VERSION ""

NS_ :

BS_:

BU_: XXX

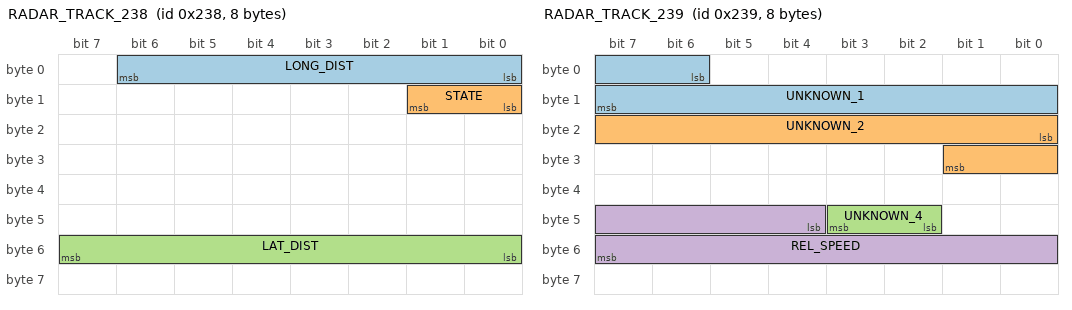
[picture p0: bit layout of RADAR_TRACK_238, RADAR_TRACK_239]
BO_ 568 RADAR_TRACK_238: 8 RADAR
 SG_ LONG_DIST : 6|7@0+ (1,0) [0|127] "m" XXX
 SG_ STATE : 9|2@0+ (1,0) [0|3] "" XXX
 SG_ LAT_DIST : 55|8@0- (0.1,0) [-12.8|12.7] "m" XXX

BO_ 569 RADAR_TRACK_239: 8 RADAR
 SG_ UNKNOWN_1 : 6|10@1+ (1,0) [0|1023] "" XXX
 SG_ UNKNOWN_2 : 16|10@1+ (1,0) [0|1023] "" XXX
 SG_ UNKNOWN_4 : 42|2@1+ (1,0) [0|3] "" XXX
 SG_ REL_SPEED : 44|12@1- (0.016,0) [-32.768|32.752] "m/s" XXX

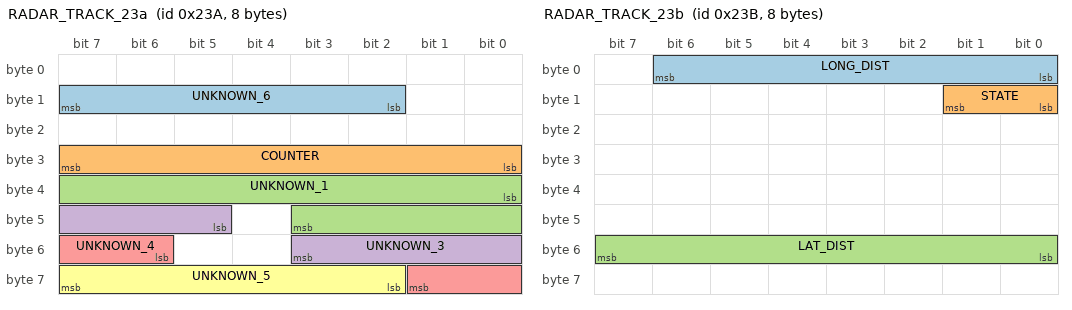
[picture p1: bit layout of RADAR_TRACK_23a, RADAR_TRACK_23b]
BO_ 570 RADAR_TRACK_23a: 8 RADAR
 SG_ UNKNOWN_6 : 10|6@1+ (1,0) [0|63] "" XXX
 SG_ COUNTER : 31|8@0+ (1,0) [0|255] "" XXX
 SG_ UNKNOWN_1 : 32|12@1+ (1,0) [0|4095] "" XXX
 SG_ UNKNOWN_3 : 45|7@1+ (1,0) [0|127] "" XXX
 SG_ UNKNOWN_4 : 54|4@1+ (1,0) [0|15] "" XXX
 SG_ UNKNOWN_5 : 63|6@0+ (1,0) [0|63] "" XXX

BO_ 571 RADAR_TRACK_23b: 8 RADAR
 SG_ LONG_DIST : 6|7@0+ (1,0) [0|127] "m" XXX
 SG_ STATE : 9|2@0+ (1,0) [0|3] "" XXX
 SG_ LAT_DIST : 55|8@0- (0.1,0) [-12.8|12.7] "m" XXX

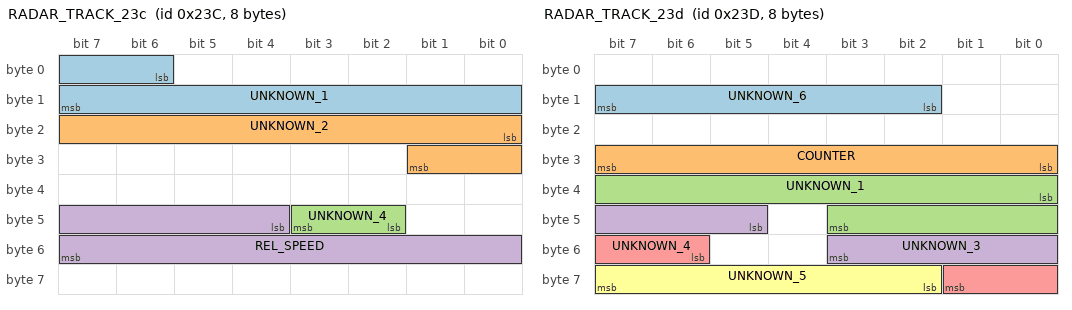
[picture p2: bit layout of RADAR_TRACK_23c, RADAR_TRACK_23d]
BO_ 572 RADAR_TRACK_23c: 8 RADAR
 SG_ UNKNOWN_1 : 6|10@1+ (1,0) [0|1023] "" XXX
 SG_ UNKNOWN_2 : 16|10@1+ (1,0) [0|1023] "" XXX
 SG_ UNKNOWN_4 : 42|2@1+ (1,0) [0|3] "" XXX
 SG_ REL_SPEED : 44|12@1- (0.016,0) [-32.768|32.752] "m/s" XXX

BO_ 573 RADAR_TRACK_23d: 8 RADAR
 SG_ UNKNOWN_6 : 10|6@1+ (1,0) [0|63] "" XXX
 SG_ COUNTER : 31|8@0+ (1,0) [0|255] "" XXX
 SG_ UNKNOWN_1 : 32|12@1+ (1,0) [0|4095] "" XXX
 SG_ UNKNOWN_3 : 45|7@1+ (1,0) [0|127] "" XXX
 SG_ UNKNOWN_4 : 54|4@1+ (1,0) [0|15] "" XXX
 SG_ UNKNOWN_5 : 63|6@0+ (1,0) [0|63] "" XXX

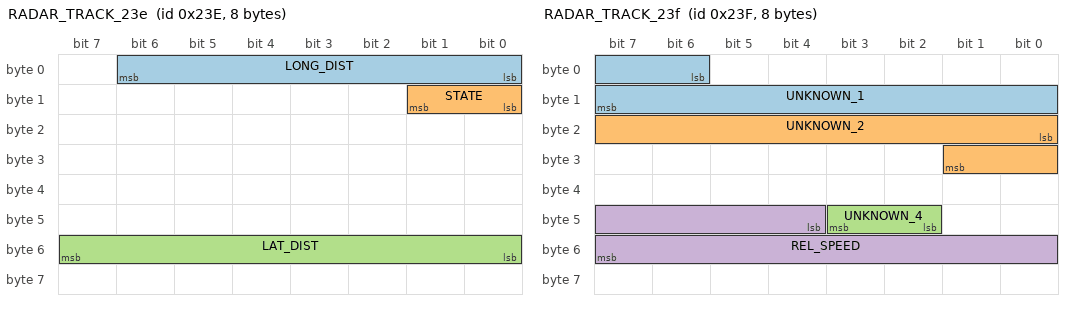
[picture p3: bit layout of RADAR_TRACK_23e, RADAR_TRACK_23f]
BO_ 574 RADAR_TRACK_23e: 8 RADAR
 SG_ LONG_DIST : 6|7@0+ (1,0) [0|127] "m" XXX
 SG_ STATE : 9|2@0+ (1,0) [0|3] "" XXX
 SG_ LAT_DIST : 55|8@0- (0.1,0) [-12.8|12.7] "m" XXX

BO_ 575 RADAR_TRACK_23f: 8 RADAR
 SG_ UNKNOWN_1 : 6|10@1+ (1,0) [0|1023] "" XXX
 SG_ UNKNOWN_2 : 16|10@1+ (1,0) [0|1023] "" XXX
 SG_ UNKNOWN_4 : 42|2@1+ (1,0) [0|3] "" XXX
 SG_ REL_SPEED : 44|12@1- (0.016,0) [-32.768|32.752] "m/s" XXX

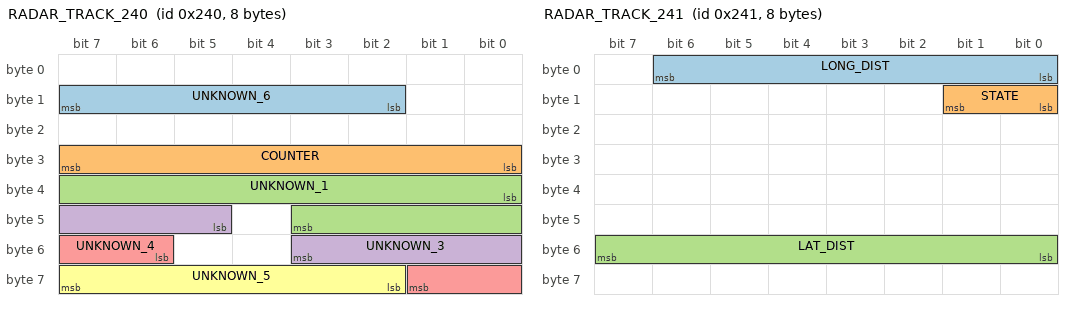
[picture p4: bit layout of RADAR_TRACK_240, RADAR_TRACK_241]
BO_ 576 RADAR_TRACK_240: 8 RADAR
 SG_ UNKNOWN_6 : 10|6@1+ (1,0) [0|63] "" XXX
 SG_ COUNTER : 31|8@0+ (1,0) [0|255] "" XXX
 SG_ UNKNOWN_1 : 32|12@1+ (1,0) [0|4095] "" XXX
 SG_ UNKNOWN_3 : 45|7@1+ (1,0) [0|127] "" XXX
 SG_ UNKNOWN_4 : 54|4@1+ (1,0) [0|15] "" XXX
 SG_ UNKNOWN_5 : 63|6@0+ (1,0) [0|63] "" XXX

BO_ 577 RADAR_TRACK_241: 8 RADAR
 SG_ LONG_DIST : 6|7@0+ (1,0) [0|127] "m" XXX
 SG_ STATE : 9|2@0+ (1,0) [0|3] "" XXX
 SG_ LAT_DIST : 55|8@0- (0.1,0) [-12.8|12.7] "m" XXX

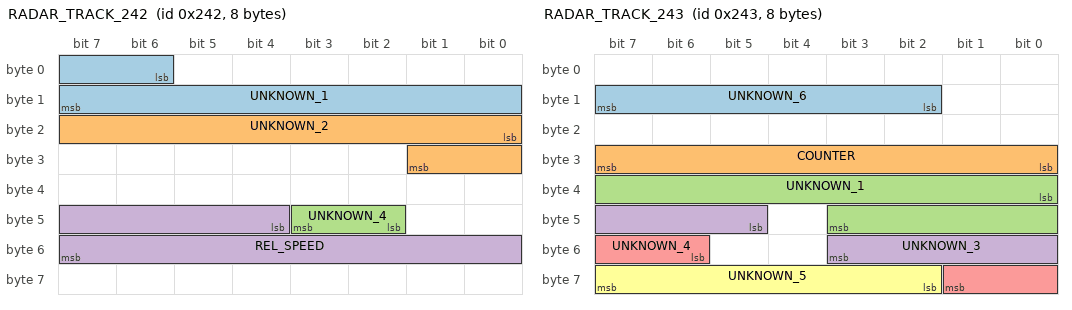
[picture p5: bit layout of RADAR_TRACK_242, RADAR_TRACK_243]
BO_ 578 RADAR_TRACK_242: 8 RADAR
 SG_ UNKNOWN_1 : 6|10@1+ (1,0) [0|1023] "" XXX
 SG_ UNKNOWN_2 : 16|10@1+ (1,0) [0|1023] "" XXX
 SG_ UNKNOWN_4 : 42|2@1+ (1,0) [0|3] "" XXX
 SG_ REL_SPEED : 44|12@1- (0.016,0) [-32.768|32.752] "m/s" XXX

BO_ 579 RADAR_TRACK_243: 8 RADAR
 SG_ UNKNOWN_6 : 10|6@1+ (1,0) [0|63] "" XXX
 SG_ COUNTER : 31|8@0+ (1,0) [0|255] "" XXX
 SG_ UNKNOWN_1 : 32|12@1+ (1,0) [0|4095] "" XXX
 SG_ UNKNOWN_3 : 45|7@1+ (1,0) [0|127] "" XXX
 SG_ UNKNOWN_4 : 54|4@1+ (1,0) [0|15] "" XXX
 SG_ UNKNOWN_5 : 63|6@0+ (1,0) [0|63] "" XXX

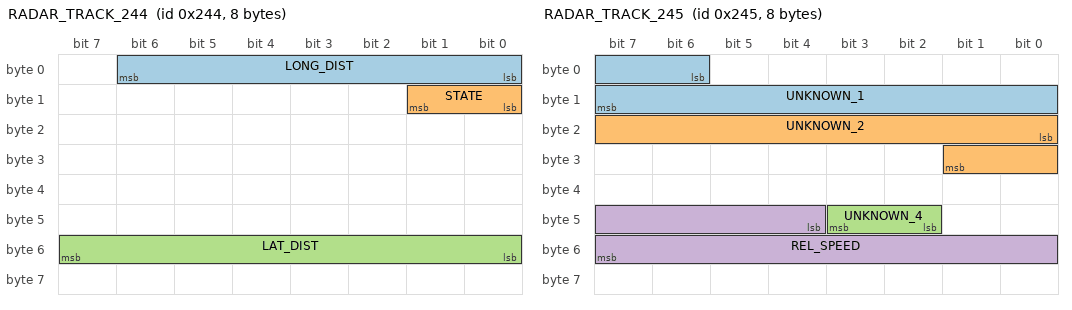
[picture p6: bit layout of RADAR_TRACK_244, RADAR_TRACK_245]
BO_ 580 RADAR_TRACK_244: 8 RADAR
 SG_ LONG_DIST : 6|7@0+ (1,0) [0|127] "m" XXX
 SG_ STATE : 9|2@0+ (1,0) [0|3] "" XXX
 SG_ LAT_DIST : 55|8@0- (0.1,0) [-12.8|12.7] "m" XXX

BO_ 581 RADAR_TRACK_245: 8 RADAR
 SG_ UNKNOWN_1 : 6|10@1+ (1,0) [0|1023] "" XXX
 SG_ UNKNOWN_2 : 16|10@1+ (1,0) [0|1023] "" XXX
 SG_ UNKNOWN_4 : 42|2@1+ (1,0) [0|3] "" XXX
 SG_ REL_SPEED : 44|12@1- (0.016,0) [-32.768|32.752] "m/s" XXX

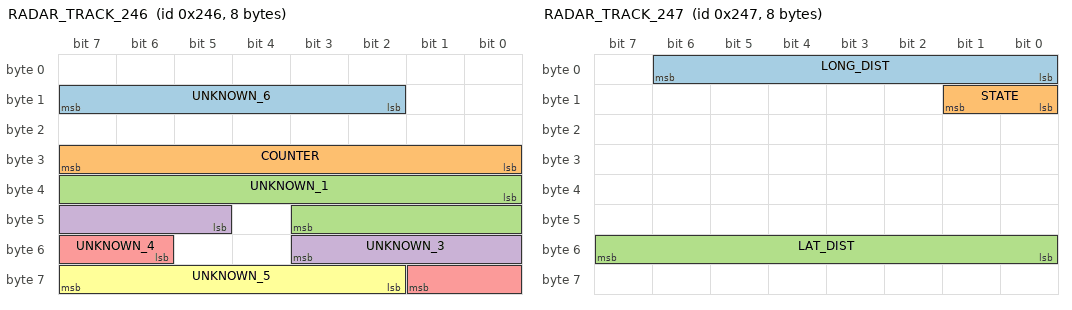
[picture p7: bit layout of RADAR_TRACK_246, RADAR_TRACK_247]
BO_ 582 RADAR_TRACK_246: 8 RADAR
 SG_ UNKNOWN_6 : 10|6@1+ (1,0) [0|63] "" XXX
 SG_ COUNTER : 31|8@0+ (1,0) [0|255] "" XXX
 SG_ UNKNOWN_1 : 32|12@1+ (1,0) [0|4095] "" XXX
 SG_ UNKNOWN_3 : 45|7@1+ (1,0) [0|127] "" XXX
 SG_ UNKNOWN_4 : 54|4@1+ (1,0) [0|15] "" XXX
 SG_ UNKNOWN_5 : 63|6@0+ (1,0) [0|63] "" XXX

BO_ 583 RADAR_TRACK_247: 8 RADAR
 SG_ LONG_DIST : 6|7@0+ (1,0) [0|127] "m" XXX
 SG_ STATE : 9|2@0+ (1,0) [0|3] "" XXX
 SG_ LAT_DIST : 55|8@0- (0.1,0) [-12.8|12.7] "m" XXX

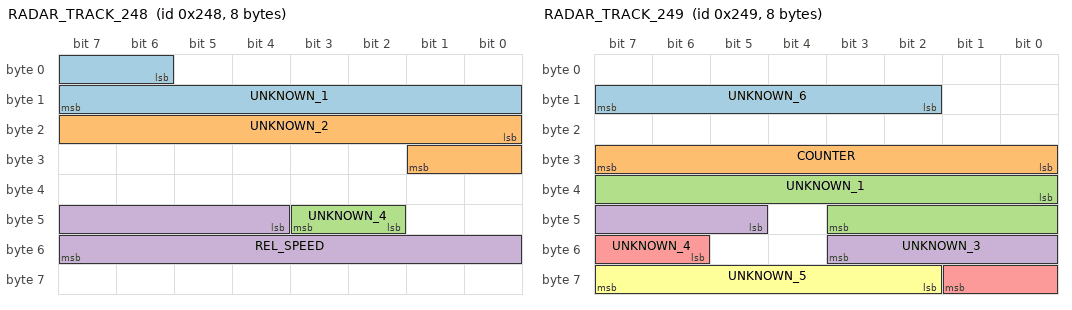
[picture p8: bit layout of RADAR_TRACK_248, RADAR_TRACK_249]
BO_ 584 RADAR_TRACK_248: 8 RADAR
 SG_ UNKNOWN_1 : 6|10@1+ (1,0) [0|1023] "" XXX
 SG_ UNKNOWN_2 : 16|10@1+ (1,0) [0|1023] "" XXX
 SG_ UNKNOWN_4 : 42|2@1+ (1,0) [0|3] "" XXX
 SG_ REL_SPEED : 44|12@1- (0.016,0) [-32.768|32.752] "m/s" XXX

BO_ 585 RADAR_TRACK_249: 8 RADAR
 SG_ UNKNOWN_6 : 10|6@1+ (1,0) [0|63] "" XXX
 SG_ COUNTER : 31|8@0+ (1,0) [0|255] "" XXX
 SG_ UNKNOWN_1 : 32|12@1+ (1,0) [0|4095] "" XXX
 SG_ UNKNOWN_3 : 45|7@1+ (1,0) [0|127] "" XXX
 SG_ UNKNOWN_4 : 54|4@1+ (1,0) [0|15] "" XXX
 SG_ UNKNOWN_5 : 63|6@0+ (1,0) [0|63] "" XXX

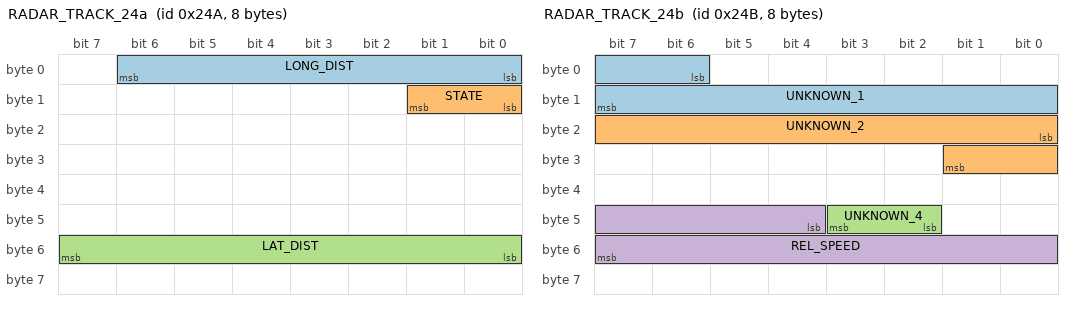
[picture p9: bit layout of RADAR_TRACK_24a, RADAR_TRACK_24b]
BO_ 586 RADAR_TRACK_24a: 8 RADAR
 SG_ LONG_DIST : 6|7@0+ (1,0) [0|127] "m" XXX
 SG_ STATE : 9|2@0+ (1,0) [0|3] "" XXX
 SG_ LAT_DIST : 55|8@0- (0.1,0) [-12.8|12.7] "m" XXX

BO_ 587 RADAR_TRACK_24b: 8 RADAR
 SG_ UNKNOWN_1 : 6|10@1+ (1,0) [0|1023] "" XXX
 SG_ UNKNOWN_2 : 16|10@1+ (1,0) [0|1023] "" XXX
 SG_ UNKNOWN_4 : 42|2@1+ (1,0) [0|3] "" XXX
 SG_ REL_SPEED : 44|12@1- (0.016,0) [-32.768|32.752] "m/s" XXX

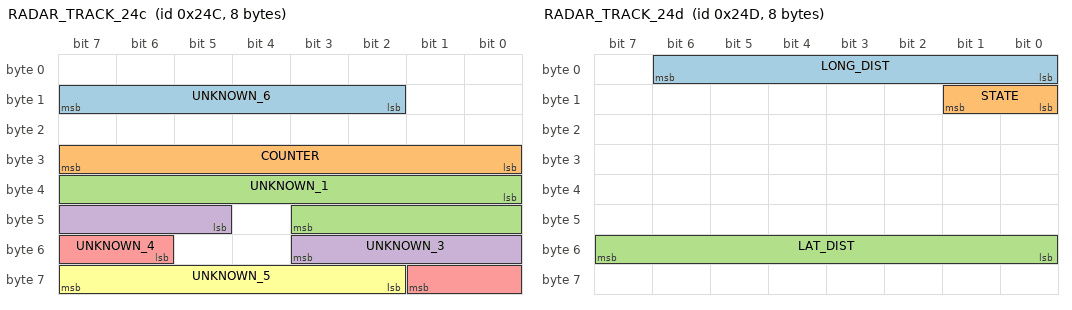
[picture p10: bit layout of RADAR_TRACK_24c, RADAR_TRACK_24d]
BO_ 588 RADAR_TRACK_24c: 8 RADAR
 SG_ UNKNOWN_6 : 10|6@1+ (1,0) [0|63] "" XXX
 SG_ COUNTER : 31|8@0+ (1,0) [0|255] "" XXX
 SG_ UNKNOWN_1 : 32|12@1+ (1,0) [0|4095] "" XXX
 SG_ UNKNOWN_3 : 45|7@1+ (1,0) [0|127] "" XXX
 SG_ UNKNOWN_4 : 54|4@1+ (1,0) [0|15] "" XXX
 SG_ UNKNOWN_5 : 63|6@0+ (1,0) [0|63] "" XXX

BO_ 589 RADAR_TRACK_24d: 8 RADAR
 SG_ LONG_DIST : 6|7@0+ (1,0) [0|127] "m" XXX
 SG_ STATE : 9|2@0+ (1,0) [0|3] "" XXX
 SG_ LAT_DIST : 55|8@0- (0.1,0) [-12.8|12.7] "m" XXX

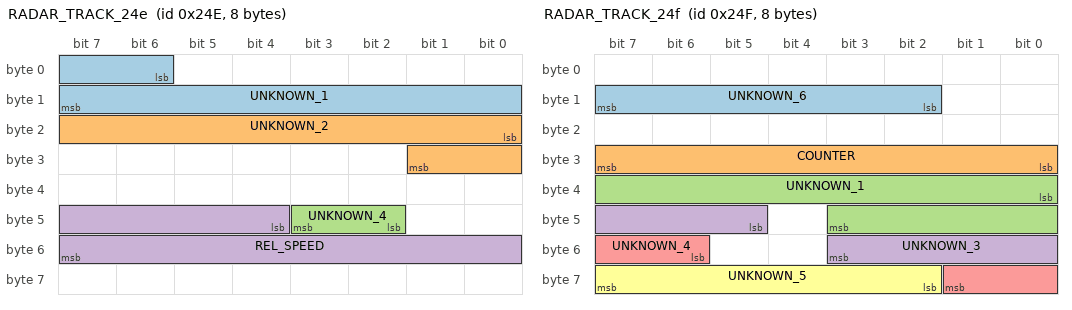
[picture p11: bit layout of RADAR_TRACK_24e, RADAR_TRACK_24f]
BO_ 590 RADAR_TRACK_24e: 8 RADAR
 SG_ UNKNOWN_1 : 6|10@1+ (1,0) [0|1023] "" XXX
 SG_ UNKNOWN_2 : 16|10@1+ (1,0) [0|1023] "" XXX
 SG_ UNKNOWN_4 : 42|2@1+ (1,0) [0|3] "" XXX
 SG_ REL_SPEED : 44|12@1- (0.016,0) [-32.768|32.752] "m/s" XXX

BO_ 591 RADAR_TRACK_24f: 8 RADAR
 SG_ UNKNOWN_6 : 10|6@1+ (1,0) [0|63] "" XXX
 SG_ COUNTER : 31|8@0+ (1,0) [0|255] "" XXX
 SG_ UNKNOWN_1 : 32|12@1+ (1,0) [0|4095] "" XXX
 SG_ UNKNOWN_3 : 45|7@1+ (1,0) [0|127] "" XXX
 SG_ UNKNOWN_4 : 54|4@1+ (1,0) [0|15] "" XXX
 SG_ UNKNOWN_5 : 63|6@0+ (1,0) [0|63] "" XXX

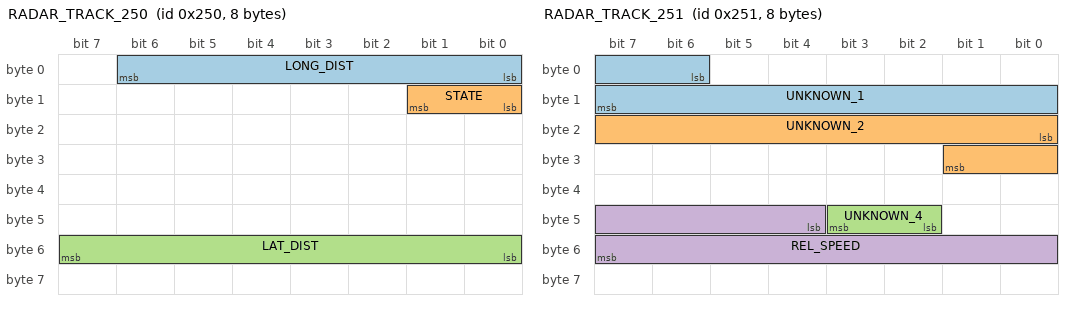
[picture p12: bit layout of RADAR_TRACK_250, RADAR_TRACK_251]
BO_ 592 RADAR_TRACK_250: 8 RADAR
 SG_ LONG_DIST : 6|7@0+ (1,0) [0|127] "m" XXX
 SG_ STATE : 9|2@0+ (1,0) [0|3] "" XXX
 SG_ LAT_DIST : 55|8@0- (0.1,0) [-12.8|12.7] "m" XXX

BO_ 593 RADAR_TRACK_251: 8 RADAR
 SG_ UNKNOWN_1 : 6|10@1+ (1,0) [0|1023] "" XXX
 SG_ UNKNOWN_2 : 16|10@1+ (1,0) [0|1023] "" XXX
 SG_ UNKNOWN_4 : 42|2@1+ (1,0) [0|3] "" XXX
 SG_ REL_SPEED : 44|12@1- (0.016,0) [-32.768|32.752] "m/s" XXX

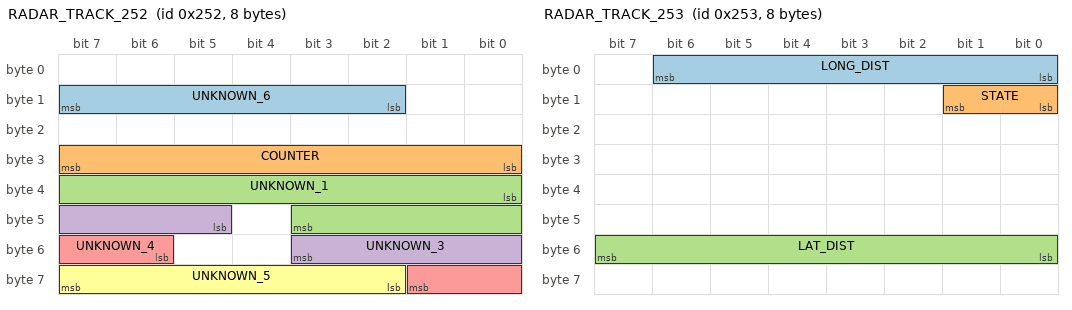
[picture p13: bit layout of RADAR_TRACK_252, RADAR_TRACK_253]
BO_ 594 RADAR_TRACK_252: 8 RADAR
 SG_ UNKNOWN_6 : 10|6@1+ (1,0) [0|63] "" XXX
 SG_ COUNTER : 31|8@0+ (1,0) [0|255] "" XXX
 SG_ UNKNOWN_1 : 32|12@1+ (1,0) [0|4095] "" XXX
 SG_ UNKNOWN_3 : 45|7@1+ (1,0) [0|127] "" XXX
 SG_ UNKNOWN_4 : 54|4@1+ (1,0) [0|15] "" XXX
 SG_ UNKNOWN_5 : 63|6@0+ (1,0) [0|63] "" XXX

BO_ 595 RADAR_TRACK_253: 8 RADAR
 SG_ LONG_DIST : 6|7@0+ (1,0) [0|127] "m" XXX
 SG_ STATE : 9|2@0+ (1,0) [0|3] "" XXX
 SG_ LAT_DIST : 55|8@0- (0.1,0) [-12.8|12.7] "m" XXX

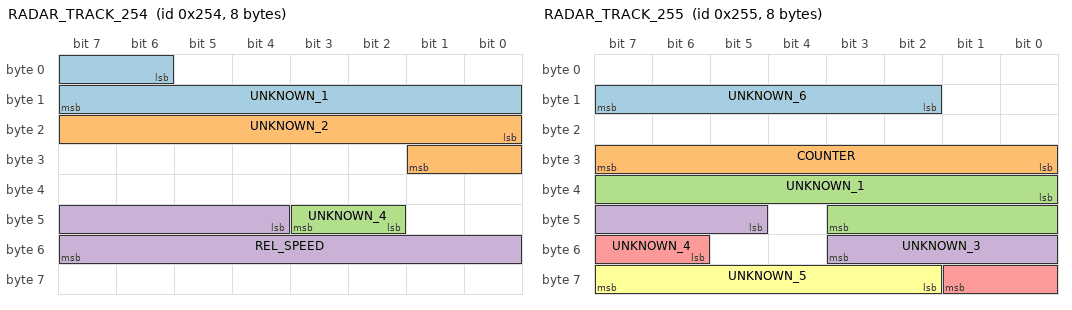
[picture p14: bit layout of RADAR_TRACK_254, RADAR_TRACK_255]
BO_ 596 RADAR_TRACK_254: 8 RADAR
 SG_ UNKNOWN_1 : 6|10@1+ (1,0) [0|1023] "" XXX
 SG_ UNKNOWN_2 : 16|10@1+ (1,0) [0|1023] "" XXX
 SG_ UNKNOWN_4 : 42|2@1+ (1,0) [0|3] "" XXX
 SG_ REL_SPEED : 44|12@1- (0.016,0) [-32.768|32.752] "m/s" XXX

BO_ 597 RADAR_TRACK_255: 8 RADAR
 SG_ UNKNOWN_6 : 10|6@1+ (1,0) [0|63] "" XXX
 SG_ COUNTER : 31|8@0+ (1,0) [0|255] "" XXX
 SG_ UNKNOWN_1 : 32|12@1+ (1,0) [0|4095] "" XXX
 SG_ UNKNOWN_3 : 45|7@1+ (1,0) [0|127] "" XXX
 SG_ UNKNOWN_4 : 54|4@1+ (1,0) [0|15] "" XXX
 SG_ UNKNOWN_5 : 63|6@0+ (1,0) [0|63] "" XXX
